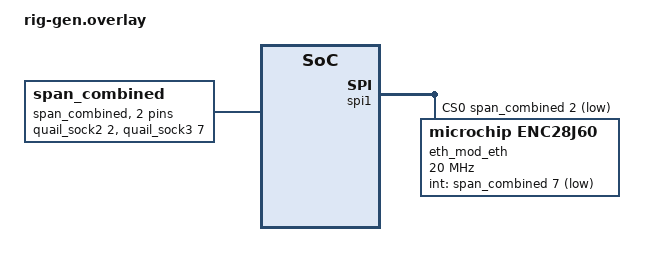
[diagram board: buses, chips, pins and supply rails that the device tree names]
/* generated by rigc — do not edit; the rig file is the source of truth
 * rig: quail_eth_span  board: mikroe_quail/stm32f427xx/rig
 */

/* carrier-exported sockets, synthesized as gpio-nexus nodes */
/ {
	span_combined: span_combined {
		#gpio-cells = <2>;
		gpio-map-mask = <0xffffffff 0xffffffc0>;
		gpio-map-pass-thru = <0 0x3f>;
		gpio-map = <2 0 &quail_sock2 2 0>,
			   <7 0 &quail_sock3 7 0>;
	};
};

&spi1 {
	cs-gpios = <&span_combined 2 1 /* ACTIVE_LOW */>;
	eth_mod_eth: eth@0 {
		compatible = "microchip,enc28j60";
		spi-max-frequency = <20000000>;
		local-mac-address = [00 00 00 00 00 00];
		zephyr,random-mac-address;
		reg = <0>;
		int-gpios = <&span_combined 7 0x1>;	/* INT */
		status = "okay";
	};
};
